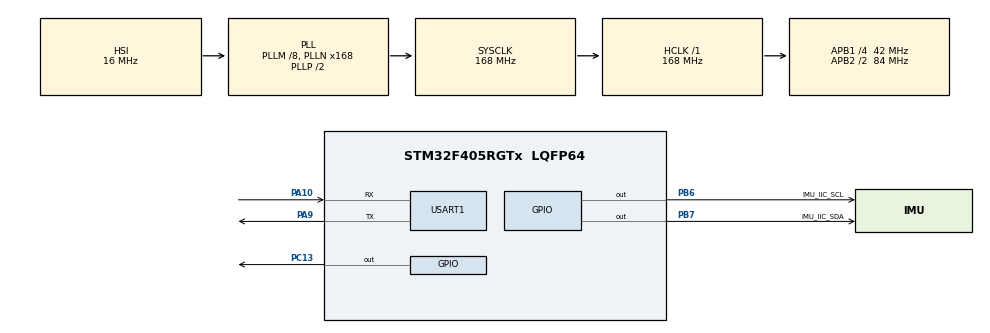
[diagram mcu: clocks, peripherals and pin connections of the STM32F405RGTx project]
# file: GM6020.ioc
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Dma.Request0=USART1_TX
Dma.Request1=USART1_RX
Dma.USART1_RX.1.Direction=DMA_PERIPH_TO_MEMORY
Dma.USART1_RX.1.FIFOMode=DMA_FIFOMODE_DISABLE
Dma.USART1_RX.1.Instance=DMA2_Stream2
Dma.USART1_RX.1.MemDataAlignment=DMA_MDATAALIGN_BYTE
Dma.USART1_RX.1.MemInc=DMA_MINC_ENABLE
Dma.USART1_RX.1.Mode=DMA_NORMAL
Dma.USART1_RX.1.PeriphDataAlignment=DMA_PDATAALIGN_BYTE
Dma.USART1_RX.1.PeriphInc=DMA_PINC_DISABLE
Dma.USART1_RX.1.Priority=DMA_PRIORITY_LOW
Dma.USART1_TX.0.Direction=DMA_MEMORY_TO_PERIPH
Dma.USART1_TX.0.FIFOMode=DMA_FIFOMODE_DISABLE
Dma.USART1_TX.0.Instance=DMA2_Stream7
Dma.USART1_TX.0.MemDataAlignment=DMA_MDATAALIGN_BYTE
Dma.USART1_TX.0.MemInc=DMA_MINC_ENABLE
Dma.USART1_TX.0.Mode=DMA_NORMAL
Dma.USART1_TX.0.PeriphDataAlignment=DMA_PDATAALIGN_BYTE
Dma.USART1_TX.0.PeriphInc=DMA_PINC_DISABLE
Dma.USART1_TX.0.Priority=DMA_PRIORITY_LOW
FREERTOS.Tasks01=imuTask,24,128,ImuTask,Default,NULL,Dynamic,NULL,NULL;usartTask,24,128,UsartTask,Default,NULL,Dynamic,NULL,NULL
Mcu.Family=STM32F4
Mcu.Name=STM32F405RGTx
Mcu.Package=LQFP64
NVIC.DMA2_Stream2_IRQn=true\:5\:0\:false\:false\:true\:true\:false\:true\:true
NVIC.DMA2_Stream7_IRQn=true\:5\:0\:false\:false\:true\:true\:false\:true\:true
NVIC.PriorityGroup=NVIC_PRIORITYGROUP_4
NVIC.TIM7_IRQn=true\:15\:0\:false\:false\:true\:false\:false\:true\:true
NVIC.TimeBase=TIM7_IRQn
NVIC.TimeBaseIP=TIM7
PA10.Mode=Asynchronous
PA10.Signal=USART1_RX
PA13.Mode=Serial_Wire
PA13.Signal=SYS_JTMS-SWDIO
PA14.Mode=Serial_Wire
PA14.Signal=SYS_JTCK-SWCLK
PA9.Mode=Asynchronous
PA9.Signal=USART1_TX
PB6.GPIO_Label=IMU_IIC_SCL
PB6.GPIO_ModeDefaultOutputPP=GPIO_MODE_OUTPUT_OD
PB6.GPIO_PuPd=GPIO_PULLUP
PB6.Signal=GPIO_Output
PB7.GPIO_Label=IMU_IIC_SDA
PB7.GPIO_ModeDefaultOutputPP=GPIO_MODE_OUTPUT_OD
PB7.GPIO_PuPd=GPIO_PULLUP
PB7.Signal=GPIO_Output
PC13-ANTI_TAMP.GPIO_PuPd=GPIO_PULLUP
PC13-ANTI_TAMP.PinState=GPIO_PIN_RESET
PC13-ANTI_TAMP.Signal=GPIO_Output
PH0-OSC_IN.Mode=HSE-External-Oscillator
PH0-OSC_IN.Signal=RCC_OSC_IN
PH1-OSC_OUT.Mode=HSE-External-Oscillator
PH1-OSC_OUT.Signal=RCC_OSC_OUT
ProjectManager.HeapSize=0x200
ProjectManager.StackSize=0x400
ProjectManager.TargetToolchain=MDK-ARM V5.32
RCC.48MHZClocksFreq_Value=84000000
RCC.AHBFreq_Value=168000000
RCC.APB1CLKDivider=RCC_HCLK_DIV4
RCC.APB1Freq_Value=42000000
RCC.APB1TimFreq_Value=84000000
RCC.APB2CLKDivider=RCC_HCLK_DIV2
RCC.APB2Freq_Value=84000000
RCC.APB2TimFreq_Value=168000000
RCC.CortexFreq_Value=168000000
RCC.HCLKFreq_Value=168000000
RCC.HSE_VALUE=25000000
RCC.HSI_VALUE=16000000
RCC.LSE_VALUE=32768
RCC.PLLM=8
RCC.PLLN=168
RCC.SYSCLKFreq_VALUE=168000000
RCC.SYSCLKSource=RCC_SYSCLKSOURCE_PLLCLK
RCC.VCOOutputFreq_Value=336000000
USART1.VirtualMode=VM_ASYNC
VP_FREERTOS_VS_CMSIS_V2.Mode=CMSIS_V2
VP_SYS_VS_tim7.Mode=TIM7
board=custom

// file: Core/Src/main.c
/* USER CODE BEGIN Header */
/**
 ******************************************************************************
 * @file           : main.c
 * @brief          : Main program body
 ******************************************************************************
 * @attention
 *
 * Copyright (c) 2024 STMicroelectronics.
 * All rights reserved.
 *
 * This software is licensed under terms that can be found in the LICENSE file
 * in the root directory of this software component.
 * If no LICENSE file comes with this software, it is provided AS-IS.
 *
 ******************************************************************************
 */
/* USER CODE END Header */
#include "main.h"
#include "cmsis_os.h"
#include "dma.h"
#include "usart.h"
#include "gpio.h"

void SystemClock_Config(void);
void MX_FREERTOS_Init(void);

int main(void)
{

  /* MCU Configuration--------------------------------------------------------*/

  /* Reset of all peripherals, Initializes the Flash interface and the Systick. */
  HAL_Init();

  /* Configure the system clock */
  SystemClock_Config();

  /* Initialize all configured peripherals */
  MX_GPIO_Init();
  MX_DMA_Init();
  MX_USART1_UART_Init();
  /* USER CODE BEGIN 2 */
//  char str[50] = "helloworld\r\n";
//  HAL_UART_Transmit(&huart1, (uint8_t *)str, strlen(str), HAL_MAX_DELAY);

  /* USER CODE END 2 */

  /* Init scheduler */
  osKernelInitialize();  /* Call init function for freertos objects (in freertos.c) */
  MX_FREERTOS_Init();

  /* Start scheduler */
  osKernelStart();
  /* We should never get here as control is now taken by the scheduler */
  /* Infinite loop */
  while (1)
  {

  }
}

void SystemClock_Config(void)
{
  RCC_OscInitTypeDef RCC_OscInitStruct = {0};
  RCC_ClkInitTypeDef RCC_ClkInitStruct = {0};

  /** Configure the main internal regulator output voltage
  */
  __HAL_RCC_PWR_CLK_ENABLE();
  __HAL_PWR_VOLTAGESCALING_CONFIG(PWR_REGULATOR_VOLTAGE_SCALE1);

  /** Initializes the RCC Oscillators according to the specified parameters
  * in the RCC_OscInitTypeDef structure.
  */
  RCC_OscInitStruct.OscillatorType = RCC_OSCILLATORTYPE_HSI;
  RCC_OscInitStruct.HSIState = RCC_HSI_ON;
  RCC_OscInitStruct.HSICalibrationValue = RCC_HSICALIBRATION_DEFAULT;
  RCC_OscInitStruct.PLL.PLLState = RCC_PLL_ON;
  RCC_OscInitStruct.PLL.PLLSource = RCC_PLLSOURCE_HSI;
  RCC_OscInitStruct.PLL.PLLM = 8;
  RCC_OscInitStruct.PLL.PLLN = 168;
  RCC_OscInitStruct.PLL.PLLP = RCC_PLLP_DIV2;
  RCC_OscInitStruct.PLL.PLLQ = 4;
  if (HAL_RCC_OscConfig(&RCC_OscInitStruct) != HAL_OK)
  {
    Error_Handler();
  }

  /** Initializes the CPU, AHB and APB buses clocks
  */
  RCC_ClkInitStruct.ClockType = RCC_CLOCKTYPE_HCLK|RCC_CLOCKTYPE_SYSCLK
                              |RCC_CLOCKTYPE_PCLK1|RCC_CLOCKTYPE_PCLK2;
  RCC_ClkInitStruct.SYSCLKSource = RCC_SYSCLKSOURCE_PLLCLK;
  RCC_ClkInitStruct.AHBCLKDivider = RCC_SYSCLK_DIV1;
  RCC_ClkInitStruct.APB1CLKDivider = RCC_HCLK_DIV4;
  RCC_ClkInitStruct.APB2CLKDivider = RCC_HCLK_DIV2;

  if (HAL_RCC_ClockConfig(&RCC_ClkInitStruct, FLASH_LATENCY_5) != HAL_OK)
  {
    Error_Handler();
  }
}

void HAL_TIM_PeriodElapsedCallback(TIM_HandleTypeDef *htim)
{
  if (htim->Instance == TIM7) {
    HAL_IncTick();
  }
}

void Error_Handler(void)
{
  __disable_irq();
  while (1)
  {
  }
}

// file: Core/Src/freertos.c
/* USER CODE BEGIN Header */
/**
 ******************************************************************************
 * File Name          : freertos.c
 * Description        : Code for freertos applications
 ******************************************************************************
 * @attention
 *
 * Copyright (c) 2024 STMicroelectronics.
 * All rights reserved.
 *
 * This software is licensed under terms that can be found in the LICENSE file
 * in the root directory of this software component.
 * If no LICENSE file comes with this software, it is provided AS-IS.
 *
 ******************************************************************************
 */
/* USER CODE END Header */

#include "FreeRTOS.h"
#include "task.h"
#include "main.h"
#include "cmsis_os.h"

/* USER CODE BEGIN Includes */
#include "usart.h"
/* USER CODE END Includes */

/* USER CODE BEGIN Variables */
float roll, pitch, yaw;
/* USER CODE END Variables */
/* Definitions for imuTask */
osThreadId_t imuTaskHandle;
const osThreadAttr_t imuTask_attributes = {
    .name = "imuTask",
    .stack_size = 128 * 4,
    .priority = (osPriority_t)osPriorityNormal,
};
/* Definitions for usartTask */
osThreadId_t usartTaskHandle;
const osThreadAttr_t usartTask_attributes = {
    .name = "usartTask",
    .stack_size = 128 * 4,
    .priority = (osPriority_t)osPriorityNormal,
};

void ImuTask(void *argument);
void UsartTask(void *argument);

void MX_FREERTOS_Init(void); /* (MISRA C 2004 rule 8.1) */

void MX_FREERTOS_Init(void)
{

  /* Create the thread(s) */
  /* creation of imuTask */
  imuTaskHandle = osThreadNew(ImuTask, NULL, &imuTask_attributes);

  /* creation of usartTask */
  usartTaskHandle = osThreadNew(UsartTask, NULL, &usartTask_attributes);

}

void ImuTask(void *argument)
{
  /* USER CODE BEGIN ImuTask */
  int ret = 0;
  do
  {
    ret = MPU6050_Init(GPIOB, GPIO_PIN_6, GPIO_PIN_7);
  } while (ret);
  /* Infinite loop */
  for (;;)
  {
    while (mpu_dmp_get_data(&pitch, &roll, &yaw))
      ;
    osDelay(5);
  }
  /* USER CODE END ImuTask */
}

void UsartTask(void *argument)
{
  /* USER CODE BEGIN UsartTask */
  char str[50];
  /* Infinite loop */
  for (;;)
  {
    sprintf(str, "pitch: %f, roll: %f, yaw: %f\r\n", pitch, roll, yaw);
    HAL_UART_Transmit(&huart1, (uint8_t *)str, strlen(str), HAL_MAX_DELAY);
    osDelay(1000);
  }
  /* USER CODE END UsartTask */
}
